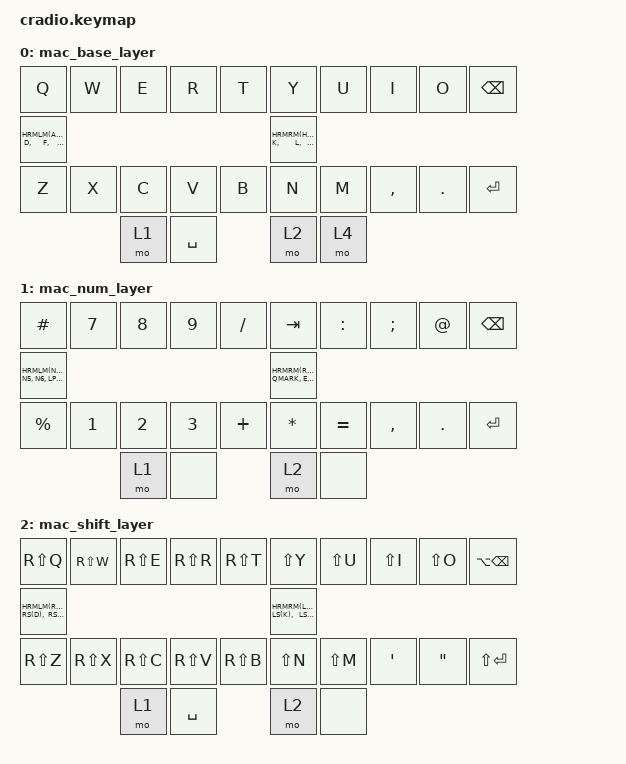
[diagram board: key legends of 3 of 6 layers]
// Copyright (c) 2022 The ZMK Contributors
// SPDX-License-identifier: MIT

#include <behaviors.dtsi>
#include <dt-bindings/zmk/keys.h>
#include <dt-bindings/zmk/bt.h>
#include <dt-bindings/zmk/outputs.h>

// Home row mods macro
#define HRMLM(k1,k2,k3,k4,k5) &ht LSHIFT k1 &ht LCTRL k2 &ht LALT k3 &ht LGUI k4 &ht LC(LS(LALT)) k5
#define HRMRM(k1,k2,k3,k4,k5) &ht RC(RS(RALT)) k1 &ht RGUI k2  &ht LALT k3 &ht RCTRL k4 &ht RSHIFT k5

// Layer definitions
#define DFLT  0 // default layer

&caps_word {
    continue-list = <UNDERSCORE MINUS>;
};

&mt {
   flavor = "tap-preferred";
   tapping_term_ms = <200>;
};

&sk {
    ignore-modifiers;
    release-after-ms = <2000>;
    quick-release;

};

&sl {
    release-after-ms = <3000>;
};

/ {
    behaviors {
      ht: hold_tap {
          label = "hold_tap";
          compatible = "zmk,behavior-hold-tap";
          #binding-cells = <2>;
          flavor = "tap-preferred";
          tapping-term-ms = <220>;
          quick-tap-ms = <150>;
          global-quick-tap;
          bindings = <&kp>, <&kp>;
      };
    };

   conditional_layers {
       compatible = "zmk,conditional-layers";
        tri_layer2 {
            if-layers = <1 2>;
            then-layer = <3>;
        };

    };

    combos {
        compatible = "zmk,combos";
        // q en backspace

    combo_settings {
        timeout-ms = <150>;
        key-positions = <0 9>;
        bindings = <&to 5>;
        };
    };

    macros {
        smijl: smijl {
            label = "ZM_smijl";
            compatible = "zmk,behavior-macro";
            #binding-cells = <0>;
            bindings
                = <&macro_tap &kp COLON &kp MINUS &kp RPAR>
                ;
        };
    };

    keymap {
        compatible = "zmk,keymap";
        
    mac_base_layer {
        bindings = <
        &kp Q  &kp W   &kp E   &kp R  &kp T      &kp Y    &kp U   &kp I     &kp O    &kp BSPC
        HRMLM(A,    S,      D,      F,     G)    HRMRM(H,       J,      K,        L,       P)
        &kp Z  &kp X   &kp C   &kp V  &kp B      &kp N    &kp M   &kp COMMA &kp DOT  &kp ENTER
                          &mo 1  &kp SPACE   &mo 2  &mo 4 
            >;
        };
   	mac_num_layer {
        bindings = < 
        &kp HASH &kp N7  &kp N8  &kp N9  &kp FSLH	 &kp TAB  &kp COLON   &kp SEMI  &kp AT  &kp BSPC
        HRMLM(N0, N4, N5, N6, LPAR)    	  HRMRM(RPAR, MINUS, QMARK, EXCL, AMPS) 
        &kp PERCENT   &kp N1  &kp N2  &kp N3 &kp PLUS     &kp STAR  &kp EQUAL  &kp COMMA  &kp DOT  &kp ENTER
                    &mo 1    &none 	 &mo 2   &none
            >;
        };
	mac_shift_layer {
        bindings = <
        &kp RS(Q) &kp RS(W)  &kp RS(E) &kp RS(R) &kp RS(T)   &kp LS(Y) &kp LS(U) &kp LS(I) &kp LS(O) &kp LA(BSPC)
        HRMLM(RS(A),  RS(S),   RS(D),  RS(F),  RS(G))    HRMRM(LS(H),   LS(J),  LS(K),   LS(L),  LS(P))
        &kp RS(Z)  &kp RS(X)   &kp RS(C)   &kp RS(V)  &kp RS(B)      &kp LS(N)    &kp LS(M)   &kp SQT &kp DQT  &kp LS(ENTER)
                           &mo 1  &kp SPACE   &mo 2  &none
            >;
        };

    mac_symbol2_layer {
        bindings = <
   	    	&kp LA(N)  &kp LA(GRAVE) &kp LA(E) &kp LA(U) &kp LA(I)       &none &kp CARET  &none  &none  &kp BSPC
   		    HRMLM(LA(BSLH), LBRC, LT, LBKT, LPAR)  	   HRMRM(RPAR, RBKT, GT, RBRC, LS(LA(BSLH)))
   		    &kp TILDE  &kp GRAVE &kp DLLR &kp UNDER &kp PIPE    &none &none  &kp BSLH  &smijl  &none
                                       &mo 1   &none     &mo 2   &none
            >;
        };

    mac_nav_layer {
        bindings = <
   	    &kp ESC  &kp F2 &none  &none  &none    &kp TAB  &kp LG(LBKT)    &kp UP  &kp LG(RBKT)  &kp LA(BSPC) 
        &kp LSHIFT  &kp LCTRL     &kp LALT   &kp LGUI   &kp LC(LS(LALT))    &kp DEL  &kp LEFT   &kp DOWN   &kp RIGHT   &kp LA(UP)
        &none    &none   &none  &kp RG(RS(N4))  &none     &none  &kp LG(LEFT)   &none      &kp LG(RIGHT)    &kp LA(DOWN)
                           &kp LSHIFT     &kp SPACE        &none       &mo 4
        >;
    };
	config_layer {
            bindings = <
            &none  &none   &none  &none  &bootloader   &bootloader  &none  &none  &none  &none 
            &bt BT_SEL 0   &bt BT_SEL 1  &bt BT_SEL 2   &bt BT_SEL 3  &bt BT_SEL 4   &none  &none &none &none  &none
            &none  &none &bt BT_CLR   &none  &none  &none  &none  &none  &none  &kp ENTER
                                &to 0  &kp SPACE   &kp SPACE &to 0
            >;
        };

};
};
